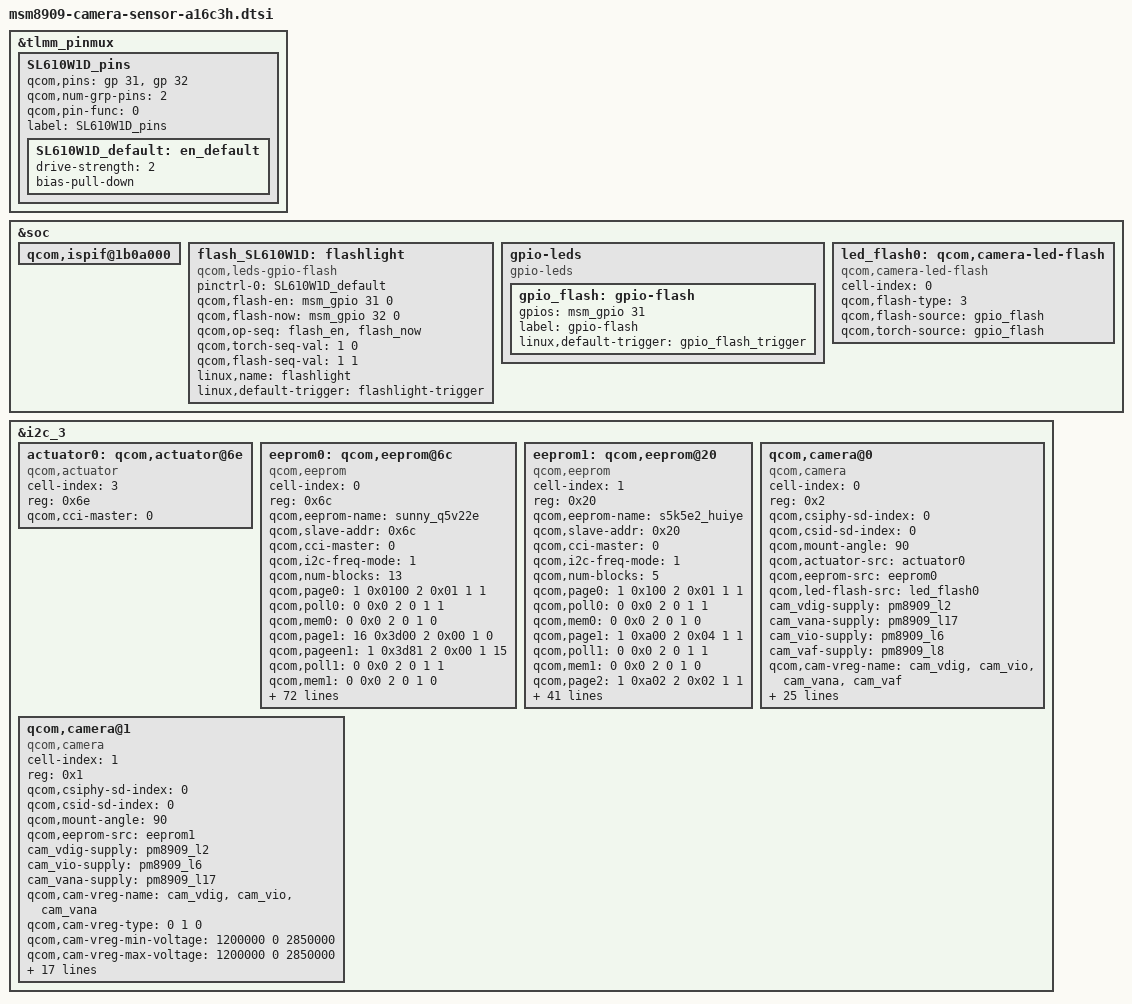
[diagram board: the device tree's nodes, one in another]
/*
 * Copyright (c) 2014, The Linux Foundation. All rights reserved.
 *
 * This program is free software; you can redistribute it and/or modify
 * it under the terms of the GNU General Public License version 2 and
 * only version 2 as published by the Free Software Foundation.
 *
 * This program is distributed in the hope that it will be useful,
 * but WITHOUT ANY WARRANTY; without even the implied warranty of
 * MERCHANTABILITY or FITNESS FOR A PARTICULAR PURPOSE.  See the
 * GNU General Public License for more details.
 * to add regulator 	vdd-supply = <&gdsc_vfe>
 */
&tlmm_pinmux {
	SL610W1D_pins {
		qcom,pins = <&gp 31>, <&gp 32>;
		qcom,num-grp-pins = <2>;
		qcom,pin-func = <0>;
		label = "SL610W1D_pins";
		SL610W1D_default: en_default {
		drive-strength = <2>;
		bias-pull-down;
		};
	};
};

&soc {
	qcom,ispif@1b0a000 {
		/delete-property/ vdd-supply;
	};

	flash_SL610W1D:flashlight {
		compatible = "qcom,leds-gpio-flash";
		status = "okay";
		pinctrl-names = "flash_default";
		pinctrl-0 = <&SL610W1D_default>;
		qcom,flash-en = <&msm_gpio 31 0>;
		qcom,flash-now = <&msm_gpio 32 0>;
		qcom,op-seq = "flash_en", "flash_now";
		qcom,torch-seq-val = <1 0>;
		qcom,flash-seq-val = <1 1>;
		linux,name = "flashlight";
		linux,default-trigger = "flashlight-trigger";
	};

	gpio-leds {
		compatible = "gpio-leds";
		status = "ok";

		gpio_flash: gpio-flash {
			gpios = <&msm_gpio 31 0>;
			label = "gpio-flash";
			linux,default-trigger = "gpio_flash_trigger";
		};
	};

	led_flash0: qcom,camera-led-flash {
		cell-index = <0>;
		compatible = "qcom,camera-led-flash";
		qcom,flash-type = <3>;
		qcom,flash-source = <&gpio_flash>;
		qcom,torch-source = <&gpio_flash>;
	};
};

&i2c_3 {
	actuator0: qcom,actuator@6e {
		cell-index = <3>;
		reg = <0x6e>;
		compatible = "qcom,actuator";
		qcom,cci-master = <0>;
	};

	eeprom0: qcom,eeprom@6c {
		cell-index = <0>;
		reg = <0x6c>;
		qcom,eeprom-name = "sunny_q5v22e";
		compatible = "qcom,eeprom";
		qcom,slave-addr = <0x6c>;
		qcom,cci-master = <0>;
		qcom,i2c-freq-mode = <1>;
		qcom,num-blocks = <13>;
		qcom,page0 = <1 0x0100 2 0x01 1 1>;
		qcom,poll0 = <0 0x0 2 0 1 1>;
		qcom,mem0 = <0 0x0 2 0 1 0>;

		qcom,page1 = <16 0x3d00 2 0x00 1 0>;
		qcom,pageen1 = <1 0x3d81 2 0x00 1 15>;
		qcom,poll1 = <0 0x0 2 0 1 1>;
		qcom,mem1 = <0 0x0 2 0 1 0>;

		qcom,page2 = <1 0x3d84 2 0xc0 1 0>;
		qcom,poll2 = <0 0x0 2 0 1 1>;
		qcom,mem2 = <0 0x0 2 0 1 0>;

		qcom,page3 = <1 0x3d85 2 0x00 1 0>;
		qcom,poll3 = <0 0x0 2 0 1 1>;
		qcom,mem3 = <0 0x0 2 0 1 0>;

		qcom,page4 = <1 0x3d86 2 0xf 1 0>;
		qcom,poll4 = <0 0x0 2 0 1 1>;
		qcom,mem4 = <0 0x0 2 0 1 0>;

		qcom,page5 = <1 0x3d81 2 0x01 1 15>;
		qcom,poll5 = <0 0x0 2 0 1 1>;
		qcom,mem5 = <16 0x3d00 2 0 1 2>;

		qcom,page6 = <16 0x3d00 2 0x00 1 0>;
		qcom,pageen6 = <1 0x3d81 2 0x00 1 15>;
		qcom,poll6 = <0 0x0 2 0 1 1>;
		qcom,mem6 = <0 0x0 2 0 1 0>;

		qcom,page7 = <16 0x3d00 2 0x00 1 0>;
		qcom,pageen7 = <1 0x3d81 2 0x00 1 15>;
		qcom,poll7 = <0 0x0 2 0 1 1>;
		qcom,mem7 = <0 0x0 2 0 1 0>;

		qcom,page8 = <1 0x3d84 2 0xc0 1 0>;
		qcom,poll8 = <0 0x0 2 0 1 1>;
		qcom,mem8 = <0 0x0 2 0 1 0>;

		qcom,page9 = <1 0x3d85 2 0x10 1 0>;
		qcom,poll9 = <0 0x0 2 0 1 1>;
		qcom,mem9 = <0 0x0 2 0 1 0>;

		qcom,page10 = <1 0x3d86 2 0x1f 1 0>;
		qcom,poll10 = <0 0x0 2 0 1 1>;
		qcom,mem10 = <0 0x0 2 0 1 0>;

		qcom,page11 = <1 0x3d81 2 0x01 1 15>;
		qcom,poll11 = <0 0x0 2 0 1 1>;
		qcom,mem11 = <16 0x3d00 2 0 1 2>;

		qcom,page12 = <16 0x3d00 2 0x00 1 0>;
		qcom,pageen12 = <1 0x3d81 2 0x00 1 15>;
		qcom,poll12 = <0 0x0 2 0 1 1>;
		qcom,mem12 = <0 0x0 2 0 1 0>;

		cam_vdig-supply = <&pm8909_l2>;
		cam_vana-supply = <&pm8909_l17>;
		cam_vio-supply = <&pm8909_l6>;
		cam_vaf-supply = <&pm8909_l8>;
		qcom,cam-vreg-name = "cam_vdig", "cam_vio", "cam_vana",
							"cam_vaf";
		qcom,cam-vreg-min-voltage = <1200000 0 2850000 2850000>;
		qcom,cam-vreg-max-voltage = <1200000 0 2850000 2900000>;
		qcom,cam-vreg-op-mode = <200000 0 80000 100000>;
		pinctrl-names = "cam_default", "cam_suspend";
		pinctrl-0 = <&cam_sensor_mclk0_default &cam_sensor_rear_default>;
		pinctrl-1 = <&cam_sensor_mclk0_sleep &cam_sensor_rear_sleep>;
		gpios = <&msm_gpio 26 0>,
			<&msm_gpio 35 0>,
			<&msm_gpio 34 0>,
			<&msm_gpio 0 0>,
			<&msm_gpio 1 0>;
		qcom,gpio-reset = <1>;
		qcom,gpio-standby = <2>;
		qcom,gpio-vana = <3>;
		qcom,gpio-vdig = <4>;
		qcom,gpio-req-tbl-num = <0 1 2 3 4>;
		qcom,gpio-req-tbl-flags = <1 0 0 0 0>;
		qcom,gpio-req-tbl-label = "CAMIF_MCLK",
			"CAM_RESET1",
			"CAM_STANDBY", 
			"CAM_VANA", 
			"CAM_VDIG";

		qcom,cam-power-seq-type = "sensor_vreg",
			"sensor_gpio", "sensor_gpio",
			"sensor_gpio", "sensor_clk" ,
			"sensor_gpio" ;
		qcom,cam-power-seq-val = "cam_vio",
			"sensor_gpio_vana",
			"sensor_gpio_vdig" ,
			"sensor_gpio_standby",
			"sensor_cam_mclk" ,
			"sensor_gpio_reset" ;
		qcom,cam-power-seq-cfg-val = <1 1 1 1 23880000 1>;
		qcom,cam-power-seq-delay = <5 5 5 10 5 5>;

		clocks = <&clock_gcc clk_mclk0_clk_src>,
			<&clock_gcc clk_gcc_camss_mclk0_clk>;
		clock-names = "cam_src_clk", "cam_clk";
	};

	eeprom1: qcom,eeprom@20 {
		cell-index = <1>;
		reg = <0x20>;
		qcom,eeprom-name = "s5k5e2_huiye";
		compatible = "qcom,eeprom";
		qcom,slave-addr = <0x20>;
		qcom,cci-master = <0>;
		qcom,i2c-freq-mode = <1>;
		qcom,num-blocks = <5>;
		qcom,page0 = <1 0x100 2 0x01 1 1>;
		qcom,poll0 = <0 0x0 2 0 1 1>;
		qcom,mem0 = <0 0x0 2 0 1 0>;

		qcom,page1 = <1 0xa00 2 0x04 1 1>;
		qcom,poll1 = <0 0x0 2 0 1 1>;
		qcom,mem1 = <0 0x0 2 0 1 0>;

		qcom,page2 = <1 0xa02 2 0x02 1 1>;
		qcom,pageen2 = <1 0xa00 2 0x01 1 10>;
		qcom,poll2 = <0 0x0 2 0 1 1>;
		qcom,mem2 = <64 0xa04 2 0 1 0>;

		qcom,page3 = <1 0xa00 2 0x04 1 1>;
		qcom,poll3 = <0 0x0 2 0 1 1>;
		qcom,mem3 = <0 0x0 2 0 1 0>;

		qcom,page4 = <1 0xa02 2 0x00 1 1>;
		qcom,poll4 = <0 0x0 2 0 1 1>;
		qcom,mem4 = <0 0x0 2 0 1 0>;

		cam_vdig-supply = <&pm8909_l2>;
		cam_vio-supply = <&pm8909_l6>;
		cam_vana-supply = <&pm8909_l17>;
		qcom,cam-vreg-name = "cam_vdig", "cam_vio", "cam_vana";
		qcom,cam-vreg-type = <0 1 0>;
		qcom,cam-vreg-min-voltage = <1200000 0 2850000>;
		qcom,cam-vreg-max-voltage = <1200000 0 2850000>;
		qcom,cam-vreg-op-mode = <200000 0 80000>;
		pinctrl-names = "cam_default", "cam_suspend";
		pinctrl-0 = <&cam_sensor_mclk1_default &cam_sensor_front_default>;
		pinctrl-1 = <&cam_sensor_mclk1_sleep &cam_sensor_front_sleep>;
		gpios = <&msm_gpio 27 0>,
			<&msm_gpio 28 0>,
			<&msm_gpio 0 0>,
			<&msm_gpio 33 0>;
		qcom,gpio-reset = <1>;
		qcom,gpio-vana = <2>;
		qcom,gpio-standby = <3>;
		qcom,gpio-req-tbl-num = <0 1 2 3>;
		qcom,gpio-req-tbl-flags = <1 0 0 0>;
		qcom,gpio-req-tbl-label = "CAMIF_MCLK",
			"CAM_RESET",
			"CAM_VANA",
			"CAM_STANDBY";
		qcom,cam-power-seq-type = "sensor_vreg", 
			"sensor_vreg", 
			"sensor_vreg", 
			"sensor_gpio", 
			"sensor_clk", 
			"sensor_gpio";
		qcom,cam-power-seq-val = "cam_vio", 
			"cam_vana", "cam_vdig", 
			"sensor_gpio_standby", 
			"sensor_cam_mclk", 
			"sensor_gpio_reset";
		qcom,cam-power-seq-cfg-val = <1 1 1 1 23880000 1>;
		qcom,cam-power-seq-delay = <5 5 5 10 5 5>;

		clocks = <&clock_gcc clk_mclk1_clk_src>,
				<&clock_gcc clk_gcc_camss_mclk1_clk>;
		clock-names = "cam_src_clk", "cam_clk";
	};

	qcom,camera@0 {
		cell-index = <0>;
		compatible = "qcom,camera";
		reg = <0x2>;
		qcom,csiphy-sd-index = <0>;
		qcom,csid-sd-index = <0>;
		qcom,mount-angle = <90>;
		qcom,actuator-src = <&actuator0>;
		qcom,eeprom-src = <&eeprom0>;
		qcom,led-flash-src = <&led_flash0>;
		cam_vdig-supply = <&pm8909_l2>;
		cam_vana-supply = <&pm8909_l17>;
		cam_vio-supply = <&pm8909_l6>;
		cam_vaf-supply = <&pm8909_l8>;
		qcom,cam-vreg-name = "cam_vdig", "cam_vio", "cam_vana",
							"cam_vaf";
		qcom,cam-vreg-type = <0 1 0 0>;
		qcom,cam-vreg-min-voltage = <1200000 0 2850000 2850000>;
		qcom,cam-vreg-max-voltage = <1200000 0 2850000 2900000>;
		qcom,cam-vreg-op-mode = <200000 0 80000 100000>;
		pinctrl-names = "cam_default", "cam_suspend";
		pinctrl-0 = <&cam_sensor_mclk0_default &cam_sensor_rear_default>;
		pinctrl-1 = <&cam_sensor_mclk0_sleep &cam_sensor_rear_sleep>;
		gpios = <&msm_gpio 26 0>,
			<&msm_gpio 35 0>,
			<&msm_gpio 34 0>,
			<&msm_gpio 0 0>,
			<&msm_gpio 1 0>;
		qcom,gpio-reset = <1>;
		qcom,gpio-standby = <2>;
		qcom,gpio-vana = <3>;
		qcom,gpio-vdig = <4>;
		qcom,gpio-req-tbl-num = <0 1 2 3 4>;
		qcom,gpio-req-tbl-flags = <1 0 0 0 0>;
		qcom,gpio-req-tbl-label = "CAMIF_MCLK",
			"CAM_RESET1",
			"CAM_STANDBY",
			"CAM_VANA",
			"CAM_VDIG";
		qcom,sensor-position = <0>;
		qcom,sensor-mode = <0>;
		qcom,cci-master = <0>;
		status = "ok";
		clocks = <&clock_gcc clk_mclk0_clk_src>,
				<&clock_gcc clk_gcc_camss_mclk0_clk>;
		clock-names = "cam_src_clk", "cam_clk";
	};

	qcom,camera@1 {
		cell-index = <1>;
		compatible = "qcom,camera";
		reg = <0x1>;
		qcom,csiphy-sd-index = <0>;
		qcom,csid-sd-index = <0>;
		qcom,mount-angle = <90>;
		qcom,eeprom-src = <&eeprom1>;
		cam_vdig-supply = <&pm8909_l2>;
		cam_vio-supply = <&pm8909_l6>;
		cam_vana-supply = <&pm8909_l17>;
		qcom,cam-vreg-name = "cam_vdig", "cam_vio", "cam_vana";
		qcom,cam-vreg-type = <0 1 0>;
		qcom,cam-vreg-min-voltage = <1200000 0 2850000>;
		qcom,cam-vreg-max-voltage = <1200000 0 2850000>;
		qcom,cam-vreg-op-mode = <200000 0 80000>;
		pinctrl-names = "cam_default", "cam_suspend";
		pinctrl-0 = <&cam_sensor_mclk1_default &cam_sensor_front_default>;
		pinctrl-1 = <&cam_sensor_mclk1_sleep &cam_sensor_front_sleep>;
		gpios = <&msm_gpio 27 0>,
			<&msm_gpio 28 0>,
			<&msm_gpio 0 0>,
			<&msm_gpio 33 0>;
		qcom,gpio-reset = <1>;
		qcom,gpio-vana = <2>;
		qcom,gpio-standby = <3>;
		qcom,gpio-req-tbl-num = <0 1 2 3>;
		qcom,gpio-req-tbl-flags = <1 0 0 0>;
		qcom,gpio-req-tbl-label = "CAMIF_MCLK",
			"CAM_RESET",
			"CAM_VANA",
			"CAM_STANDBY";
		qcom,cci-master = <0>;
		status = "ok";
		clocks = <&clock_gcc clk_mclk1_clk_src>,
				<&clock_gcc clk_gcc_camss_mclk1_clk>;
		clock-names = "cam_src_clk", "cam_clk";
	};
};
